# jbr_MDR1986VE1T register map
Registers from a debugger description file.
Registers are 32-bit, access not given, no defined reset value unless marked. A register's access mark holds for its fields unless they carry their own. Addresses are absolute; registers are grouped by the start of their names; lines under a group give offsets from that group; [hi:lo] are bit positions; {n}, {i} and the like mark numbered series; 'fields as' and 'values as' point back to an identical list; <NAME> marks a mode.

## Further device data
interrupts=NMI 0x08; HardFault 0x0C; MemManage 0x10; BusFault 0x14; UsageFault 0x18; SVC 0x2C; DebugMon 0x30; PendSV 0x38; SysTick 0x3C; WWDG 0x40; PVD 0x44; TAMPER 0x48; RTC 0x4C; FLASH 0x50; RCC 0x54; EXTI0 0x58; EXTI1 0x5C; EXTI2 0x60; EXTI3 0x64; EXTI4 0x68; DMA1Ch1 0x6C; DMA1Ch2 0x70; DMA1Ch3 0x74; DMA1Ch4 0x78; DMA1Ch5 0x7C; DMA1Ch6 0x80; DMA1Ch7 0x84; ADC1_2 0x88; USB_HP_CAN_TX 0x8C; USB_LP_CAN_RX0 0x90; CAN_RX1 0x94; CAN_SCE 0x98; EXTI9_5 0x9C; TIM1_BRK 0xA0; TIM1_UP 0xA4; TIM1_TRG_COM 0xA8; TIM1_CC 0xAC; TIM2 0xB0; I2C1_EV 0xBC; I2C1_ER 0xC0; SPI1 0xCC; USART1 0xD4; USART2 0xD8; EXTI15_10 0xE0; RTCAlarm 0xE4; USBWakeup 0xE8

## EEPROM
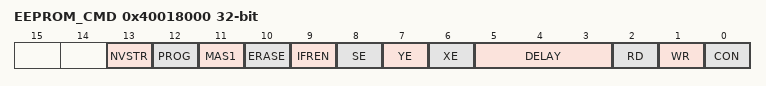
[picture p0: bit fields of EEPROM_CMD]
0x40018000 EEPROM_CMD
  [13] NVSTR, [12] PROG, [11] MAS1, [10] ERASE, [9] IFREN, [8] SE, [7] YE, [6] XE, [5:3] DELAY, [2] RD, [1] WR, [0] CON
0x40018004 EEPROM_ADR
0x40018008 EEPROM_DI
0x4001800C EEPROM_D0
0x40018010 EEPROM_KEY

## USB
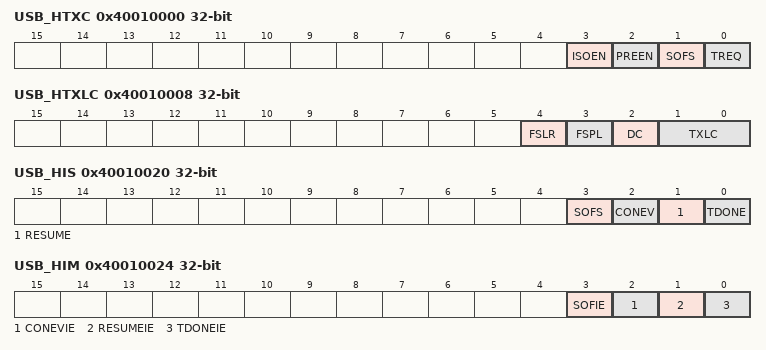
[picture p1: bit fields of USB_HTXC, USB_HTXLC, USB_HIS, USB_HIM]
0x40010000 USB_HTXC
  [3] ISOEN, [2] PREEN, [1] SOFS, [0] TREQ
0x40010004 USB_HTXT
  [1:0] TTYPE
0x40010008 USB_HTXLC
  [4] FSLR, [3] FSPL, [2] DC, [1:0] TXLC
0x4001000C USB_HTXSE
  [0] SOFEN
0x40010010 USB_HTXA
  [6:0] DEVADDR
0x40010014 USB_HTXE
  [3:0] EPADDR
0x40010018 USB_HFN_L
  [10:0] FNUM
0x4001001C USB_HFN_H
  [10:0] FNUM
0x40010020 USB_HIS
  [3] SOFS, [2] CONEV, [1] RESUME, [0] TDONE
0x40010024 USB_HIM
  [3] SOFIE, [2] CONEVIE, [1] RESUMEIE, [0] TDONEIE
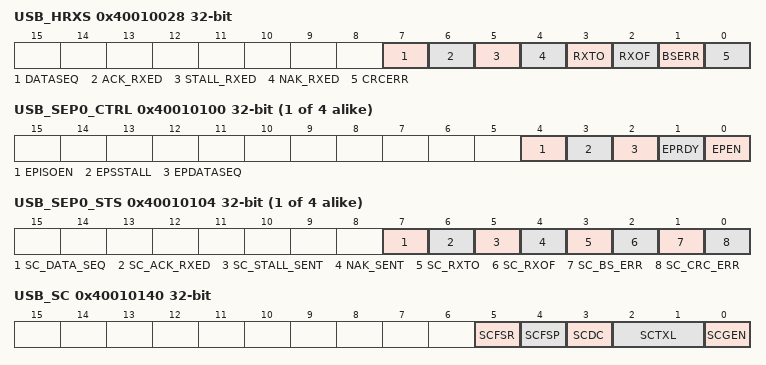
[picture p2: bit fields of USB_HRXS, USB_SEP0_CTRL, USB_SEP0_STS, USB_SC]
0x40010028 USB_HRXS
  [7] DATASEQ, [6] ACK_RXED, [5] STALL_RXED, [4] NAK_RXED, [3] RXTO, [2] RXOF, [1] BSERR, [0] CRCERR
0x4001002C USB_HRXP
  [3:0] RPID
0x40010030 USB_HRXA
  [6:0] RADDR
0x40010034 USB_HRXE
  [3:0] RXENDP
0x40010038 USB_HRXCS
  [1:0] RXLS
0x4001003C USB_HSTM
  [7:0] HSTM
0x40010080 USB_HRXFD
  [7:0] RX_FIFO_DATA
0x40010088 USB_HRXDC_L
  [15:0] FIFO_DATA_COUNT
0x4001008C USB_HRXDC_H
  [15:0] FIFO_DATA_COUNT
0x40010090 USB_HRXFC
  [0] FIFO_FORCE_EMPTY
0x400100C0 USB_HTXFD
  [7:0] TX_FIFO_DATA
0x400100D0 USB_HTXFC
  [0] FIFO_FORCE_EMPTY
{0x40010100+0x10*i} USB_SEP{i}_CTRL (i=0..3)
  [4] EPISOEN, [3] EPSSTALL, [2] EPDATASEQ, [1] EPRDY, [0] EPEN
{0x40010104+0x10*i} USB_SEP{i}_STS (i=0..3)
  [7] SC_DATA_SEQ, [6] SC_ACK_RXED, [5] SC_STALL_SENT, [4] NAK_SENT, [3] SC_RXTO, [2] SC_RXOF, [1] SC_BS_ERR, [0] SC_CRC_ERR
{0x40010108+0x10*i} USB_SEP{i}_TS (i=0..3)
  [1:0] SCTTYPE
{0x4001010C+0x10*i} USB_SEP{i}_NTS (i=0..3)
  [1:0] NTTYPE
0x40010140 USB_SC
  [5] SCFSR, [4] SCFSP, [3] SCDC, [2:1] SCTXL, [0] SCGEN
0x40010144 USB_SLS
  [1:0] SCRXLS
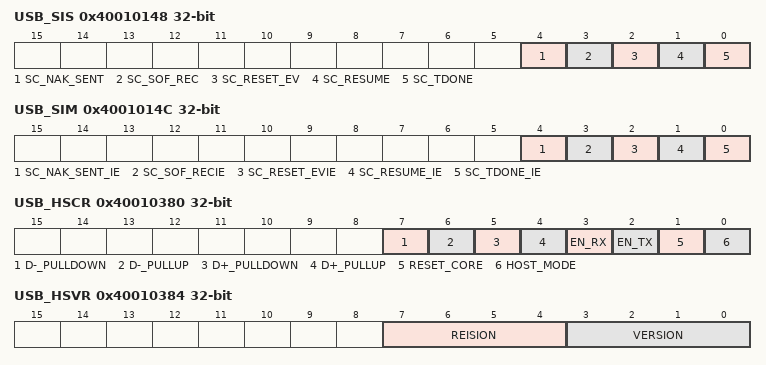
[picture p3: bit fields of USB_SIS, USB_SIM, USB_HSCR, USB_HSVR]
0x40010148 USB_SIS
  [4] SC_NAK_SENT, [3] SC_SOF_REC, [2] SC_RESET_EV, [1] SC_RESUME, [0] SC_TDONE
0x4001014C USB_SIM
  [4] SC_NAK_SENT_IE, [3] SC_SOF_RECIE, [2] SC_RESET_EVIE, [1] SC_RESUME_IE, [0] SC_TDONE_IE
0x40010150 USB_SA
  [6:0] SDEVADDR
0x40010154 USB_SFN_L
  [10:0] FRAME_NUM
0x40010158 USB_SFN_H
  [10:0] FRAME_NUM
{0x40010180+0x80*i} USB_SEP{i}_RXFD (i=0..3)
  [7:0] RX_FIFO_DATA
{0x40010188+0x80*i} USB_SEP{i}_RXFDC_L (i=0..3)
  [15:0] FIFO_DATA_COUNT
{0x4001018C+0x80*i} USB_SEP{i}_RXFDC_H (i=0..3)
  [15:0] FIFO_DATA_COUNT
{0x40010190+0x80*i} USB_SEP{i}_RXFC (i=0..3)
  [0] FIFO_FORCE_EMPTY
{0x400101C0+0x80*i} USB_SEP{i}_TXFD (i=0..3)
  [7:0] TX_FIFO_DATA
{0x400101D0+0x80*i} USB_SEP{i}_TXFDC (i=0..3)
  [0] FIFO_FORCE_EMPTY
0x40010380 USB_HSCR
  [7] D-_PULLDOWN, [6] D-_PULLUP, [5] D+_PULLDOWN, [4] D+_PULLUP, [3] EN_RX, [2] EN_TX, [1] RESET_CORE, [0] HOST_MODE
0x40010384 USB_HSVR
  [7:4] REISION, [3:0] VERSION
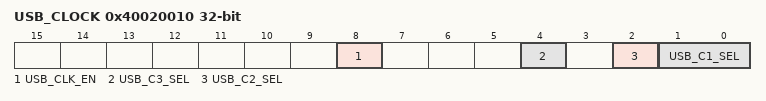
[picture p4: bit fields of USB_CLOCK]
0x40020010 USB_CLOCK
  [8] USB_CLK_EN, [4] USB_C3_SEL, [2] USB_C2_SEL, [1:0] USB_C1_SEL
